# R7FA6E2BB register map
Vendor: Renesas Electronics Corporation; Series: RA6; File version: 1.30.00
CPU: CM33 r0p4, little endian, MPU, FPU, VTOR, 4 interrupt priority bits, 96 interrupts
Registers are 32-bit, read-write, reset 0x0 unless marked. A register's access mark holds for its fields unless they carry their own. Offsets are from the block's base; [hi:lo] are bit positions; {n}, {i} and the like mark numbered series; 'fields as' and 'values as' point back to an identical list.

## I3C — I3C Bus Interface
Base 0x4011F000
0x00 PRTS reset 0x1 — Protocol Selection Register
  [0] PRTMD — Protocol Mode
0x10 CECTL — Clock Enable Control Resisters
  [0] CLKE — Clock Enable
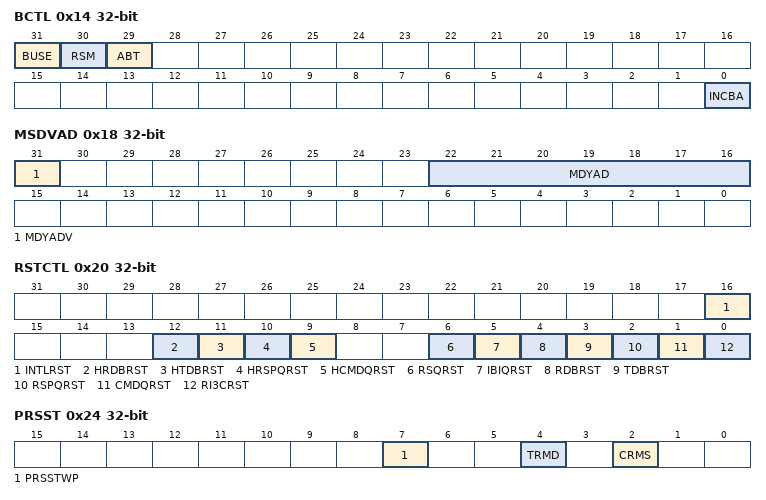
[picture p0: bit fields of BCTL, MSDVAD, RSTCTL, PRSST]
0x14 BCTL — Bus Control Register
  [31] BUSE — Bus Enable
  [30] RSM — Resume
  [29] ABT — Abort
  [0] INCBA — Include I3C Broadcast Address
0x18 MSDVAD — Master Device Address Register
  [31] MDYADV — Master Dynamic Address Valid
  [22:16] MDYAD — Master Dynamic Address
0x20 RSTCTL — Reset Control Register
  [16] INTLRST — Internal Software Reset
  [12] HRDBRST — High Priority Receive Data Buffer Software Reset
  [11] HTDBRST — High Priority Transmit Data Buffer Software Reset
  [10] HRSPQRST — High Priority Response Queue Software Reset
  [9] HCMDQRST — High Priority Command Queue Software Reset
  [6] RSQRST — Receive Status Queue Software Reset
  [5] IBIQRST — IBI Queue Software Reset
  [4] RDBRST — Receive Data Buffer Software Reset
  [3] TDBRST — Transmit Data Buffer Software Reset
  [2] RSPQRST — Response Queue Software Reset
  [1] CMDQRST — Command Queue Software Reset
  [0] RI3CRST — I3C Software Reset
0x24 PRSST — Present State Register
  [7] PRSSTWP wo — Present State Write Protect
  [4] TRMD ro — Transmit/Receive Mode
  [2] CRMS — Current Master
0x30 INST — Internal Status Register
  [10] INEF — Internal Error Flag
0x34 INSTE — Internal Status Enable Register
  [10] INEE — Internal Error Enable
0x38 INIE — Internal Interrupt Enable Register
  [10] INEIE — Internal Error Interrupt Enable
0x3C INSTFC wo — Internal Status Force Register
  [10] INEFC — Internal Error Force
0x44 DVCT ro — Device Characteristic Table Register
  [23:19] IDX — DCT Table Index
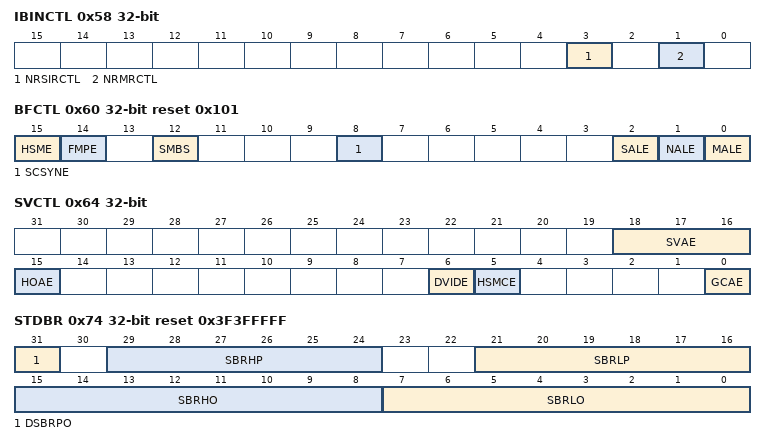
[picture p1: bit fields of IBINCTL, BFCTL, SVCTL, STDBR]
0x58 IBINCTL — IBI Notify Control Register
  [3] NRSIRCTL — Notify Rejected Slave Interrupt Request Control
  [1] NRMRCTL — Notify Rejected Master Request Control
0x60 BFCTL reset 0x101 — Bus Function Control Register
  [15] HSME — High Speed Mode Enable
  [14] FMPE — Fast,mode Plus Enable
  [12] SMBS — SMBus/I2C Bus Selection
  [8] SCSYNE — SCL Synchronous Circuit Enable
  [2] SALE — Slave Arbitration,Lost Detection Enable
  [1] NALE — NACK Transmission Arbitration,Lost Detection Enable
  [0] MALE — Master Arbitration,Lost Detection Enable
0x64 SVCTL — Slave Control Register
  [18:16] SVAE — Slave Address Enable n ( n = 0 to 2 )
  [15] HOAE — Host Address Enable
  [6] DVIDE — Device,ID Address Enable
  [5] HSMCE — Hs,mode Master Code Enable
  [0] GCAE — General Call Address Enable
0x70 REFCKCTL — Reference Clock Control Register
  [2:0] IREFCKS — Internal Reference Clock Selection
0x74 STDBR reset 0x3F3FFFFF — Standard Bit Rate Register
  [31] DSBRPO — Double the Standard Bit Rate Period for Open,Drain
  [29:24] SBRHP — Standard Bit Rate High,level Period Push,Pull
  [21:16] SBRLP — Standard Bit Rate Low,level Period Push,Pull
  [15:8] SBRHO — Standard Bit Rate High,level Period Open,Drain
  [7:0] SBRLO — Standard Bit Rate Low,level Period Open,Drain
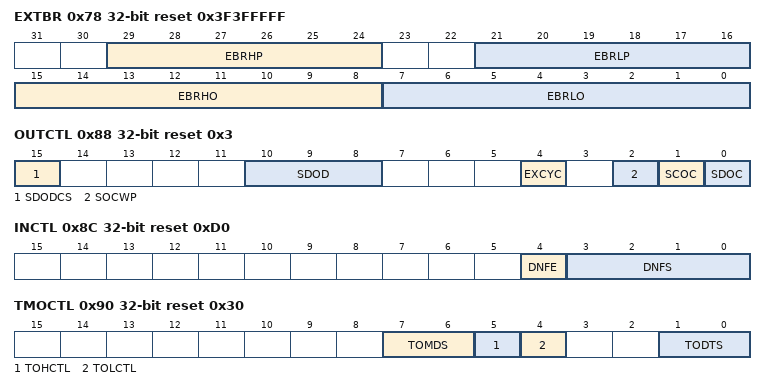
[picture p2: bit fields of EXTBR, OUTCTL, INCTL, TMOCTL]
0x78 EXTBR reset 0x3F3FFFFF — Extended Bit Rate Register
  [29:24] EBRHP — Extended Bit Rate High,level Period Push,Pull
  [21:16] EBRLP — Extended Bit Rate Low,level Period Push,Pull
  [15:8] EBRHO — Extended Bit Rate High,level Period Open,Drain
  [7:0] EBRLO — Extended Bit Rate Low,level Period Open,Drain
0x7C BFRECDT — Bus Free Condition Detection Time Register
  [8:0] FRECYC — Bus Free Condition Detection Cycle
0x80 BAVLCDT — Bus Available Condition Detection Time Register
  [8:0] AVLCYC — Bus Available Condition Detection Cycle
0x84 BIDLCDT — Bus Idle Condition Detection Time Register
  [17:0] IDLCYC — Bus Idle Condition Detection Cycle
0x88 OUTCTL reset 0x3 — Output Control Register
  [15] SDODCS — SDA Output Delay Clock Source Selection
  [10:8] SDOD — SDA Output Delay
  [4] EXCYC — Extra SCL Clock Cycle Output
  [2] SOCWP wo — SCL/SDA Output Control Write Protect
  [1] SCOC — SCL Output Control
  [0] SDOC — SDA Output Control
0x8C INCTL reset 0xD0 — Input Control Register
  [4] DNFE — Digital Noise Filter Circuit Enable
  [3:0] DNFS — Digital Noise Filter Stage Selection
0x90 TMOCTL reset 0x30 — Timeout Control Register
  [7:6] TOMDS — Timeout Operation Mode Selection
  [5] TOHCTL — Timeout H Count Control
  [4] TOLCTL — Timeout L Count Control
  [1:0] TODTS — Timeout Detection Time Selection
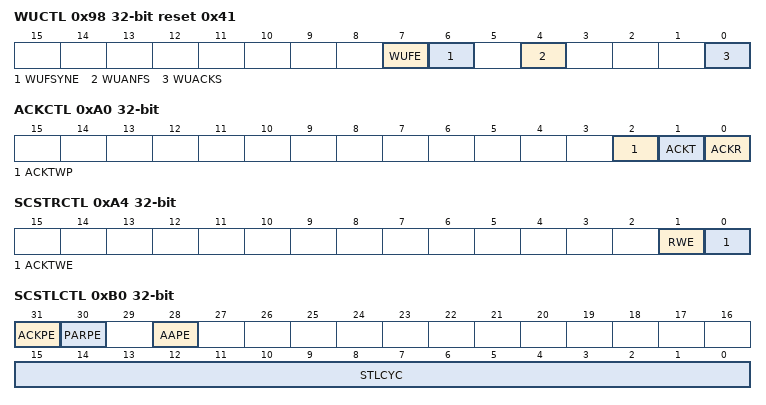
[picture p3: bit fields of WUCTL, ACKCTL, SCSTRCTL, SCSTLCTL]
0x98 WUCTL reset 0x41 — Wake Up Unit Control Register
  [7] WUFE — Wake,Up function Enable
  [6] WUFSYNE — Wake,Up function PCLK Synchronous Enable
  [4] WUANFS — Wake,Up Analog Noise Filter Selection
  [0] WUACKS — Wake,Up Acknowledge Selection
0xA0 ACKCTL — Acknowledge Control Register
  [2] ACKTWP wo — ACKT Write Protect
  [1] ACKT — Acknowledge Transmission
  [0] ACKR ro — Acknowledge Reception
0xA4 SCSTRCTL — SCL Stretch Control Register
  [1] RWE — Receive Wait Enable
  [0] ACKTWE — Acknowledge Transmission Wait Enable
0xB0 SCSTLCTL — SCL Stalling Control Register
  [31] ACKPE — ACK phase Enable
  [30] PARPE — Parity Phase Enable
  [28] AAPE — Assigned Address Phase Enable
  [15:0] STLCYC — Stalling Cycle
0xC0 SVTDLG0 — Slave Transfer Data Length Register 0
  [31:16] STDLG — Slave Transfer Data Length
0x120 STCTL — Synchronous Timing Control Register
  [0] STOE — Synchronous Timing output Enable
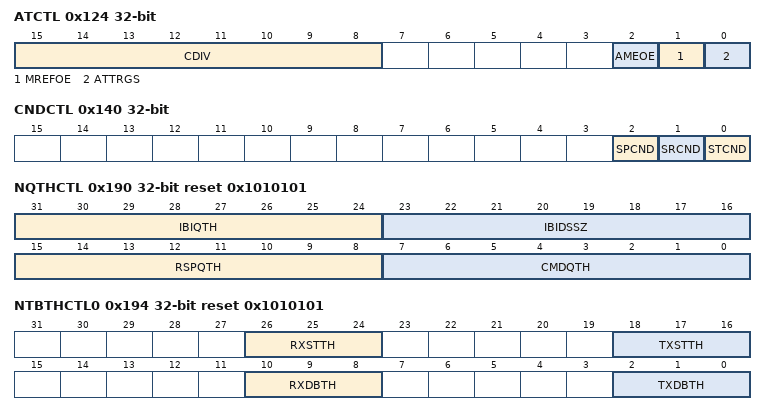
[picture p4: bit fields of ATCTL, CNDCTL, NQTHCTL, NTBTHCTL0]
0x124 ATCTL — Asynchronous Timing Control Register
  [15:8] CDIV — TCLK Counter Divide Setting
  [2] AMEOE — Additional Master,initiated bus Event Output Enable
  [1] MREFOE — MREF Output Enable (Capture Event / Counter Overflow)
  [0] ATTRGS — Asynchronous Timing Trigger Select
0x128 ATTRG — Asynchronous Timing Trigger Register
  [0] ATSTRG wo — Asynchronous Timing Software Trigger
0x12C ATCCNTE — Asynchronous Timing Contorol Counter enable Register
  [0] ATCE — Asynchronous Timing Counter Enable for MREF, MC2, SC1, SC2.
0x140 CNDCTL — Condition Control Register
  [2] SPCND — STOP (P) Condition Issuance
  [1] SRCND — Repeated START (Sr) Condition Issuance
  [0] STCND — START (S) Condition Issuance
0x150 NCMDQP wo — Normal Command Queue Port Register
0x154 NRSPQP ro — Normal Response Queue Port Register
0x158 NTDTBP0 — Normal Transfer Data Buffer Port Register 0
0x158 NTDTBP0_BY 8-bit (alternate view of NTDTBP0) — Normal Transfer Data Buffer Port Register 0
0x17C NIBIQP — Normal IBI Queue Port Register
0x180 NRSQP ro — Normal Receive Status Queue Port Register
0x184 HCMDQP wo — High Priority Command Queue Port Register
0x188 HRSPQP ro — High Priority Response Queue Port Register
0x18C HTDTBP — High Priority Transfer Data Buffer Port Register
0x190 NQTHCTL reset 0x1010101 — Normal Queue Threshold Control Register
  [31:24] IBIQTH — Normal IBI Queue Threshold
  [23:16] IBIDSSZ — Normal IBI Data Segment Size
  [15:8] RSPQTH — Normal Response Queue Threshold
  [7:0] CMDQTH — Normal Command Ready Queue Threshold
0x194 NTBTHCTL0 reset 0x1010101 — Normal Transfer Data Buffer Threshold Control Register 0
  [26:24] RXSTTH — Normal Rx Start Threshold
  [18:16] TXSTTH — Normal Tx Start Threshold
  [10:8] RXDBTH — Normal Receive Data Buffer Threshold
  [2:0] TXDBTH — Normal Transmit Data Buffer Threshold
0x1C0 NRQTHCTL reset 0x1 — Normal Receive Status Queue Threshold Control Register
  [7:0] RSQTH — Normal Receive Status Queue Threshold
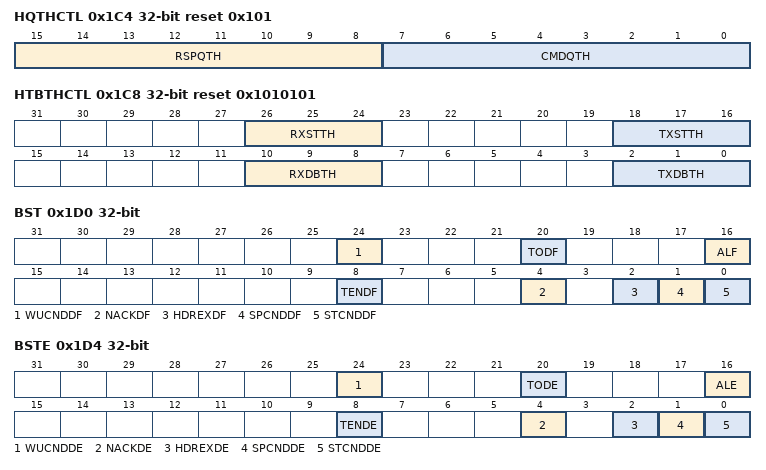
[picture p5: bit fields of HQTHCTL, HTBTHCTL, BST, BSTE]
0x1C4 HQTHCTL reset 0x101 — High Priority Queue Threshold Control Register
  [15:8] RSPQTH — High Priority Response Ready Queue Threshold
  [7:0] CMDQTH — High Priority Command Ready Queue Threshold
0x1C8 HTBTHCTL reset 0x1010101 — High Priority Transfer Data Buffer Threshold Control Register
  [26:24] RXSTTH — High Priority Rx Start Threshold
  [18:16] TXSTTH — High Priority Tx Start Threshold
  [10:8] RXDBTH — High Priority Receive Data Buffer Threshold
  [2:0] TXDBTH — High Priority Transmit Data Buffer Threshold
0x1D0 BST — Bus Status Register
  [24] WUCNDDF — Wake,Up Condition Detection Flag
  [20] TODF — Timeout Detection Flag
  [16] ALF — Arbitration Lost Flag
  [8] TENDF — Transmit End Flag
  [4] NACKDF — NACK Detection Flag
  [2] HDREXDF — HDR Exit Pattern Detection Flag
  [1] SPCNDDF — STOP Condition Detection Flag
  [0] STCNDDF — START Condition Detection Flag
0x1D4 BSTE — Bus Status Enable Register
  [24] WUCNDDE — Wake,up Condition Detection Enable
  [20] TODE — Timeout Detection Enable
  [16] ALE — Arbitration Lost Enable
  [8] TENDE — Transmit End Enable
  [4] NACKDE — NACK Detection Enable
  [2] HDREXDE — HDR Exit Pattern Detection Enable
  [1] SPCNDDE — STOP Condition Detection Enable
  [0] STCNDDE — START Condition Detection Enable
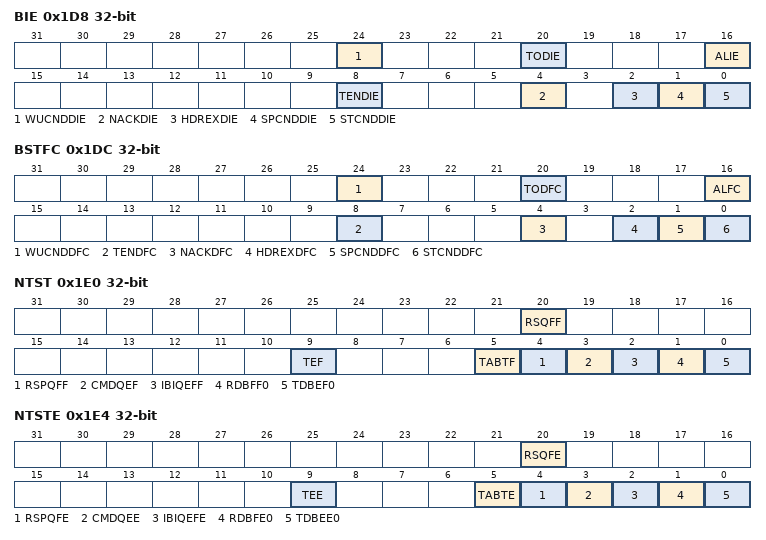
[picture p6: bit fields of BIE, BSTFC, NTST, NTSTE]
0x1D8 BIE — Bus Interrupt Enable Register
  [24] WUCNDDIE — Wake,Up Condition Detection Interrupt Enable
  [20] TODIE — Timeout Detection Interrupt Enable
  [16] ALIE — Arbitration Lost Interrupt Enable
  [8] TENDIE — Transmit End Interrupt Enable
  [4] NACKDIE — NACK Detection Interrupt Enable
  [2] HDREXDIE — HDR Exit Pattern Detection Interrupt Enable
  [1] SPCNDDIE — STOP Condition Detection Interrupt Enable
  [0] STCNDDIE — START Condition Detection Interrupt Enable
0x1DC BSTFC — Bus Status Force Register
  [24] WUCNDDFC wo — Wake,Up Condition Detection Force
  [20] TODFC wo — Timeout Detection Force
  [16] ALFC wo — Arbitration Lost Force
  [8] TENDFC wo — Transmit End Force
  [4] NACKDFC wo — NACK Detection Force
  [2] HDREXDFC wo — HDR Exit Pattern Detection Force
  [1] SPCNDDFC wo — STOP condition Detection Force
  [0] STCNDDFC wo — START condition Detection Force
0x1E0 NTST — Normal Transfer Status Register
  [20] RSQFF — Normal Receive Status Queue Full Flag
  [9] TEF — Normal Transfer Error Flag
  [5] TABTF — Normal Transfer Abort Flag
  [4] RSPQFF — Normal Response Queue Full Flag
  [3] CMDQEF — Normal Command Queue Empty Flag
  [2] IBIQEFF — Normal IBI Queue Empty/Full Flag
  [1] RDBFF0 — Normal Receive Data Buffer Full Flag 0
  [0] TDBEF0 — Normal Transmit Data Buffer Empty Flag 0
0x1E4 NTSTE — Normal Transfer Status Enable Register
  [20] RSQFE — Normal Receive Status Queue Full Enable
  [9] TEE — Normal Transfer Error Enable
  [5] TABTE — Normal Transfer Abort Enable
  [4] RSPQFE — Normal Response Queue Full Enable
  [3] CMDQEE — Normal Command Queue Empty Enable
  [2] IBIQEFE — Normal IBI Queue Empty/Full Enable
  [1] RDBFE0 — Normal Receive Data Buffer Full Enable 0
  [0] TDBEE0 — Normal Transmit Data Buffer Empty Enable 0
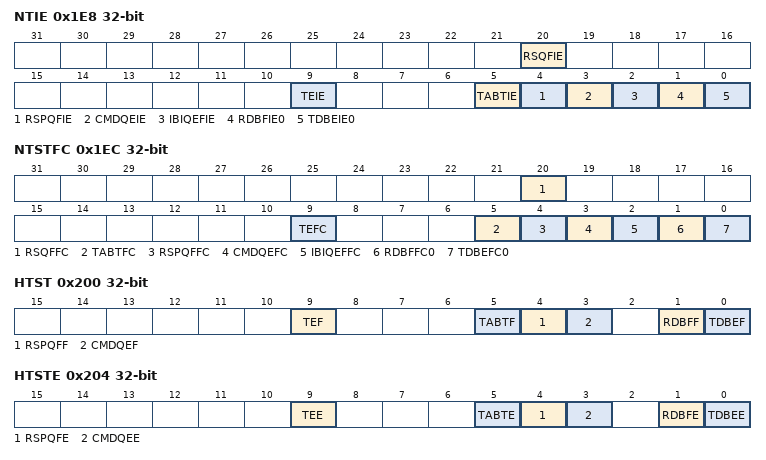
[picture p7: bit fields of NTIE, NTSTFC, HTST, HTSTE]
0x1E8 NTIE — Normal Transfer Interrupt Enable Register
  [20] RSQFIE — Normal Receive Status Queue Full Interrupt Enable
  [9] TEIE — Normal Transfer Error Interrupt Enable
  [5] TABTIE — Normal Transfer Abort Interrupt Enable
  [4] RSPQFIE — Normal Response Queue Full Interrupt Enable
  [3] CMDQEIE — Normal Command Queue Empty Interrupt Enable
  [2] IBIQEFIE — Normal IBI Queue Empty/Full Interrupt Enable
  [1] RDBFIE0 — Normal Receive Data Buffer Full Interrupt Enable 0
  [0] TDBEIE0 — Normal Transmit Data Buffer Empty Interrupt Enable 0
0x1EC NTSTFC — Normal Transfer Status Force Register
  [20] RSQFFC wo — Normal Receive Status Queue Full Force
  [9] TEFC wo — Normal Transfer Error Force
  [5] TABTFC wo — Normal Transfer Abort Force
  [4] RSPQFFC wo — Normal Response Queue Full Force
  [3] CMDQEFC wo — Normal Command Queue Empty Force
  [2] IBIQEFFC wo — Normal IBI Queue Empty/Full Force
  [1] RDBFFC0 wo — Normal Receive Data Buffer Full Force 0
  [0] TDBEFC0 wo — Normal Transmit Data Buffer Empty Force 0
0x200 HTST — High Priority Transfer Status Register
  [9] TEF — High Priority Transfer Error Flag
  [5] TABTF — High Priority Transfer Abort Flag
  [4] RSPQFF — High Priority Response Queue Full Flag
  [3] CMDQEF — High Priority Command Queue Empty Flag
  [1] RDBFF — High Priority Receive Data Buffer Full Flag
  [0] TDBEF — High Priority Transmit Data Buffer Empty Flag
0x204 HTSTE — High Priority Transfer Status Enable Register
  [9] TEE — High Priority Transfer Error Enable
  [5] TABTE — High Priority Transfer Abort Enable
  [4] RSPQFE — High Priority Response Queue Full Enable
  [3] CMDQEE — High Priority Command Queue Empty Enable
  [1] RDBFE — High Priority Receive Data Buffer Full Enable
  [0] TDBEE — High Priority Transmit Data Buffer Empty Enable
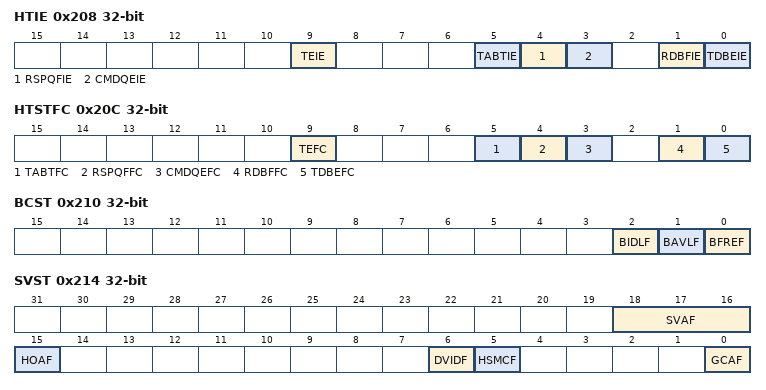
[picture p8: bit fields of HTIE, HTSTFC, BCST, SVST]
0x208 HTIE — High Priority Transfer Interrupt Enable Register
  [9] TEIE — High Priority Transfer Error Interrupt Enable
  [5] TABTIE — High Priority Transfer Abort Interrupt Enable
  [4] RSPQFIE — High Priority Response Queue Full Interrupt Enable
  [3] CMDQEIE — High Priority Command Queue Empty Interrupt Enable
  [1] RDBFIE — High Priority Receive Data Buffer Full Interrupt Enable
  [0] TDBEIE — High Priority Transmit Data Buffer Empty Interrupt Enable
0x20C HTSTFC — High Priority Transfer Status Force Register
  [9] TEFC wo — High Priority Transfer Error Force
  [5] TABTFC wo — High Priority Transfer Abort Force
  [4] RSPQFFC wo — High Priority Response Queue Full Force
  [3] CMDQEFC wo — High Priority Command Queue Empty Force
  [1] RDBFFC wo — High Priority Receive Data Buffer Full Force
  [0] TDBEFC wo — High Priority Transmit Data Buffer Empty Force
0x210 BCST ro — Bus Condition Status Register
  [2] BIDLF — Bus Idle Detection Flag
  [1] BAVLF — Bus Available Detection Flag
  [0] BFREF — Bus Free Detection Flag
0x214 SVST — Slave Status Register
  [18:16] SVAF — Slave Address Detection Flag n ( n = 0 to 2 )
  [15] HOAF — Host Address Detection Flag
  [6] DVIDF — Device,ID Address Detection Flag
  [5] HSMCF — Hs,mode Master Code Detection Flag
  [0] GCAF — General Call Address Detection Flag
0x218 WUST ro — Wake Up Unit Operating Status Register
  [0] WUASYNF — Wake,up function asynchronous operation status flag
0x21C MRCCPT ro — MsyncCNT Counter Capture Register
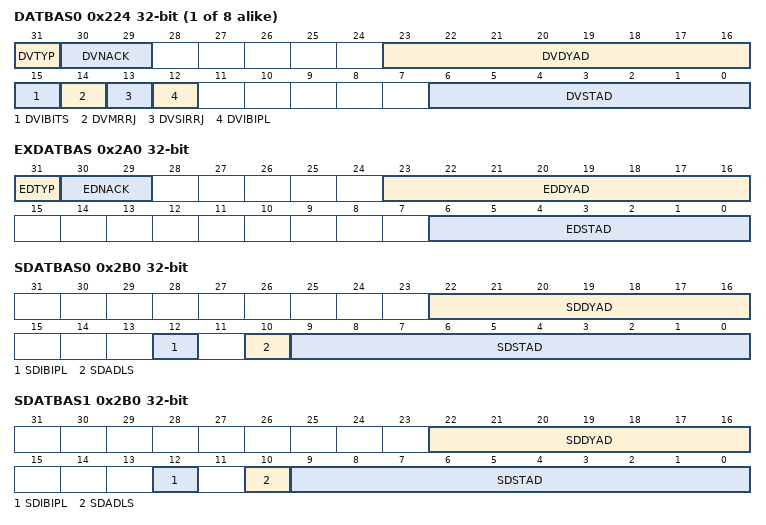
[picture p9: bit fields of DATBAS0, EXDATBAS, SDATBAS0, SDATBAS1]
{0x224+8i} DATBAS{i} (i=0..7) — Device Address Table Basic Register {i}
  [31] DVTYP — Device Type
  [30:29] DVNACK — Device NACK Retry Count
  [23:16] DVDYAD — Device I3C Dynamic Address
  [15] DVIBITS — Device IBI Time,stamp
  [14] DVMRRJ — Device In,Band Master Request Reject
  [13] DVSIRRJ — Device In,Band Slave Interrupt Request Reject
  [12] DVIBIPL — Device IBI Payload
  [6:0] DVSTAD — Device Static Address
0x2A0 EXDATBAS — Extended Device Address Table Basic Register
  [31] EDTYP — Extended Device Type
  [30:29] EDNACK — Extended Device NACK Retry Count
  [23:16] EDDYAD — Extended Device I3C Dynamic Address
  [6:0] EDSTAD — Extended Device Static Address
0x2B0 SDATBAS0 — Slave Device Address Table Basic Register 0
  [22:16] SDDYAD — Slave Device I3C Dynamic Address
  [12] SDIBIPL — Slave Device IBI Payload
  [10] SDADLS — Slave Device Address Length Selection
  [9:0] SDSTAD — Slave Device Static Address
0x2B0 SDATBAS1 (alternate view of SDATBAS0) — Slave Device Address Table Basic Register 1
  fields as SDATBAS0
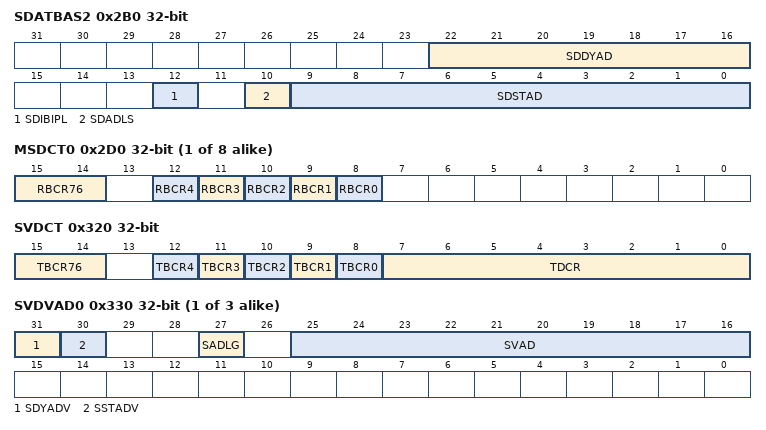
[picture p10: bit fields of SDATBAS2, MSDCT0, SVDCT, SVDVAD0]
0x2B0 SDATBAS2 (alternate view of SDATBAS0) — Slave Device Address Table Basic Register 2
  fields as SDATBAS0
{0x2D0+4i} MSDCT{i} (i=0..7) — Master Device Characteristic Table Register {i}
  [15:14] RBCR76 — Device Role
  [12] RBCR4 — Bridge Identifier
  [11] RBCR3 — Offline Capable
  [10] RBCR2 — IBI Payload
  [9] RBCR1 — IBI Request Capable
  [8] RBCR0 — Max Data Speed Limitation
0x320 SVDCT — Slave Device Characteristic Table Register
  [15:14] TBCR76 — Device Role
  [12] TBCR4 — Bridge Identifier
  [11] TBCR3 — Offline Capable
  [10] TBCR2 — IBI Payload
  [9] TBCR1 — IBI Request Capable
  [8] TBCR0 — Max Data Speed Limitation
  [7:0] TDCR — Transfar Device Characteristic Register
0x324 SDCTPIDL — Slave Device Characteristic Table Provisional ID Low Register
0x328 SDCTPIDH — Slave Device Characteristic Table Provisional ID High Register
{0x330+4i} SVDVAD{i} (i=0..2) ro — Slave Device Address Register {i}
  [31] SDYADV — Slave Dynamic Address Valid
  [30] SSTADV — Slave Static Address Valid
  [27] SADLG — Slave Address Length
  [25:16] SVAD — Slave Address
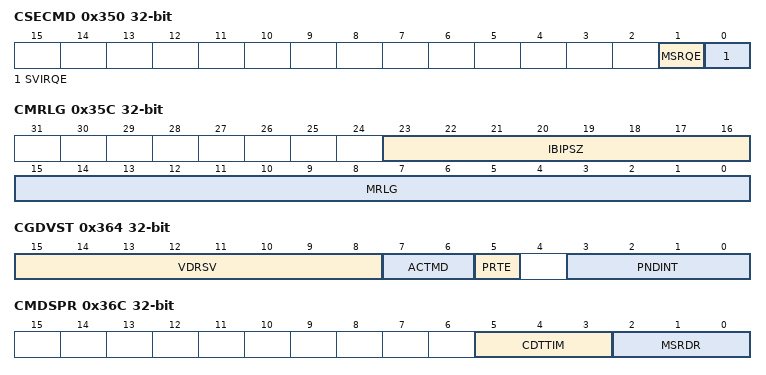
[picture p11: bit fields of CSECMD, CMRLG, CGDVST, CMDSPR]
0x350 CSECMD — CCC Slave Events Command Register
  [1] MSRQE — Mastership Requests Enable
  [0] SVIRQE — Slave Interrupt Requests Enable
0x354 CEACTST — CCC Enter Activity State Register
  [3:0] ACTST — Activity State
0x358 CMWLG — CCC Max Write Length Register
  [15:0] MWLG — Max Write Length
0x35C CMRLG — CCC Max Read Length Register
  [23:16] IBIPSZ — IBI Payload Size
  [15:0] MRLG — Max Read Length
0x360 CETSTMD ro — CCC Enter Test Mode Register
  [7:0] TSTMD — Test Mode
0x364 CGDVST — CCC Get Device Status Register
  [15:8] VDRSV — Vendor Reserved
  [7:6] ACTMD — Slave Device’s current Activity Mode
  [5] PRTE — Protocol Error
  [3:0] PNDINT — Pending Interrupt
0x368 CMDSPW — CCC Max Data Speed W (Write) Register
  [2:0] MSWDR — Maximum Sustained Write Data Rate
0x36C CMDSPR — CCC Max Data Speed R (Read) Register
  [5:3] CDTTIM — Clock to Data Turnaround Time (TSCO)
  [2:0] MSRDR — Maximum Sustained Read Data Rate
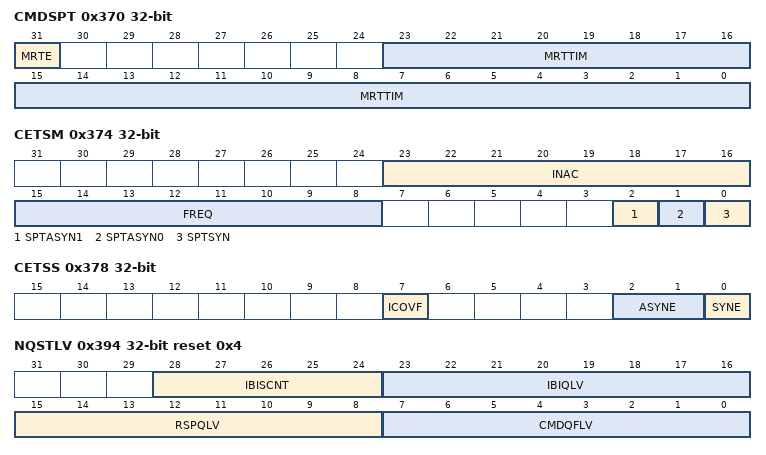
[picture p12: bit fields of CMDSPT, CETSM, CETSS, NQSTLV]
0x370 CMDSPT — CCC Max Data Speed T (Turnaround) Register
  [31] MRTE — Maximum Read Turnaround Time Enable
  [23:0] MRTTIM — Maximum Read Turnaround Time
0x374 CETSM — CCC Exchange Timing Support Information M (Mode) Register
  [23:16] INAC — Inaccuracy Byte
  [15:8] FREQ — Frequency Byte
  [2] SPTASYN1 — Support Async Mode 1
  [1] SPTASYN0 — Support Async Mode 0
  [0] SPTSYN — Supports Sync Mode
0x378 CETSS — CCC Exchange Timing Support Information S (State) Register
  [7] ICOVF — Internal Counter Overflow
  [2:1] ASYNE — Async Mode Enabled
  [0] SYNE — Sync Mode Enabled
0x380 BITCNT ro — Bit Count Register
  [4:0] BCNT — Bit Counter
0x394 NQSTLV ro reset 0x4 — Normal Queue Status Level Register
  [28:24] IBISCNT — Normal IBI Status Count
  [23:16] IBIQLV — Normal IBI Queue Level
  [15:8] RSPQLV — Normal Response Queue Level
  [7:0] CMDQFLV — Normal Command Queue Free Level
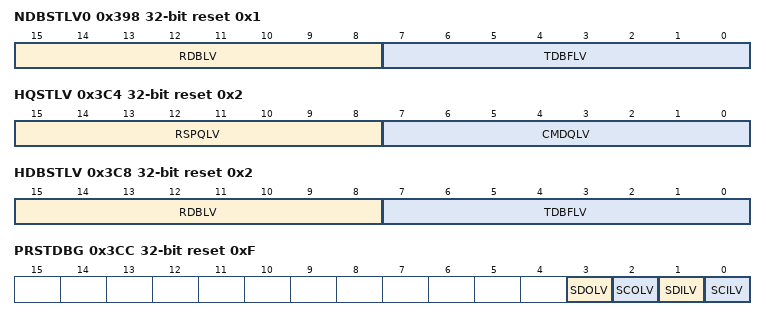
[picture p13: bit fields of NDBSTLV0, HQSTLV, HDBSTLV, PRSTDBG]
0x398 NDBSTLV0 ro reset 0x1 — Normal Data Buffer Status Level Register 0
  [15:8] RDBLV — Normal Receive Data Buffer Level
  [7:0] TDBFLV — Normal Transmit Data Buffer Free Level
0x3C0 NRSQSTLV ro — Normal Receive Status Queue Status Level Register
  [7:0] RSQLV — Normal Receive Status Queue Level
0x3C4 HQSTLV ro reset 0x2 — High Priority Queue Status Level Register
  [15:8] RSPQLV — High Priority Response Queue Level
  [7:0] CMDQLV — High Priority Command Queue Level
0x3C8 HDBSTLV ro reset 0x2 — High Priority Data Buffer Status Level Register
  [15:8] RDBLV — High Priority Receive Data Buffer Level
  [7:0] TDBFLV — High Priority Transmit Data Buffer Free Level
0x3CC PRSTDBG ro reset 0xF — Present State Debug Register
  [3] SDOLV — SDA Output Level
  [2] SCOLV — SCL Output Level
  [1] SDILV — SDA Line Signal Level
  [0] SCILV — SCL Line Signal Level
0x3D0 MSERRCNT ro — Master Error Counters Register
  [7:0] M2ECNT — M2 Error Counter
0x3E0 SC1CPT ro — SC1 Capture monitor Register
  [15:0] SC1C — SC1 Capture
0x3E4 SC2CPT ro — SC2 Capture monitor Register
  [15:0] SC2C — SC2 Capture
